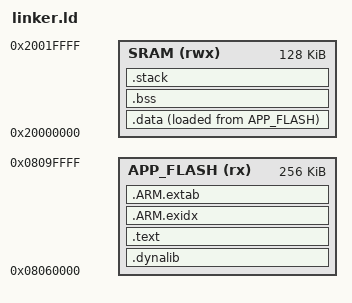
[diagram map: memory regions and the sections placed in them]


/* todo - import defines for mem layout from system module 1 */

MEMORY
{
    APP_FLASH (rx)  : ORIGIN = 0x08060000, LENGTH = 256K

    /* todo - SRAM must start also at an offset after what has been reserved for system-module 1 */
    SRAM      (rwx) : ORIGIN = 0x20000000, LENGTH = 128K
}


SECTIONS
{
    .dynalib :
    {
        link_module_jump_table_start = . ;
        KEEP(*(*.system_part1_module))
        link_module_jump_table_end = . ;
    }>APP_FLASH  AT> APP_FLASH

    .text :
    {
        . = ALIGN(4);

        link_code_location = .;
        KEEP(*(.text.irq ))
        *(.text .text.* .gnu.linkonce.t.*)
        link_code_end = .;

        . = ALIGN(0x4);

        link_const_variable_data_location = .;
        *(.rodata .rodata.* .gnu.linkonce.r.*)
        link_const_variable_data_end = .;

        . = ALIGN(0x4);

        link_constructors_location = .;
        KEEP(*(.preinit_array))
        KEEP(*(.init_array))
        KEEP (*crtbegin.o(.ctors))
        KEEP (*(EXCLUDE_FILE (*crtend.o) .ctors))
        KEEP (*(SORT(.ctors.*)))
        KEEP (*crtend.o(.ctors))
        link_constructors_end = .;

        . = ALIGN(0x4);

        link_destructors_location = .;
        KEEP (*crtbegin.o(.dtors))
        KEEP (*(EXCLUDE_FILE (*crtend.o) .dtors))
        KEEP (*(SORT(.dtors.*)))
        KEEP (*crtend.o(.dtors))
        link_destructors_end = .;

        . = ALIGN(16);

    }>APP_FLASH  AT> APP_FLASH

    /*
     * The .ARM.exidx and .ARM.extab sections are used for C++ exception handling.
     * It is located here for completeness. Bare-metal ARM projects
     * typically cannot afford the overhead associated with C++
     * exceptions handling.
     */
    .ARM.exidx :
    {
        __exidx_start = ALIGN(4);
        *(.ARM.exidx* .gnu.linkonce.armexidx.*)
        __exidx_end = .;
    } > APP_FLASH  AT> APP_FLASH

    .ARM.extab :
    {
        __extab_start = ALIGN(4);
        *(.ARM.extab*)
        __extab_end = .;
    } > APP_FLASH  AT> APP_FLASH

    .data : /* Contains the non-zero initialised global variables */
    {
        link_global_data_initial_values = LOADADDR( .data ); /* This is the location in flash of the initial values of global variables */
        link_global_data_start = .;
        *(.data*)
        link_global_data_end = .;
        . = ALIGN(., 4);
    }> SRAM AT> APP_FLASH


    .bss : /* Zero initialised memory used for zero initialised variables */
    {
        link_bss_location = ALIGN(., 4);
        *(.bss*)
        *(COMMON)
        link_bss_end = .;
        . = ALIGN(., 4);
    }> SRAM AT> SRAM

    .stack : /* Contains the initial stack */
    {
        link_stack_location = ALIGN(., 4);
        *(.stack)
        . = ALIGN(MAX(link_stack_location + __STACKSIZE__ , .), 4);
        link_stack_end = .;
    }> SRAM AT> SRAM

    /DISCARD/ :
    {
        *(.ARM.attributes*)
        *(.comment)
        *(.init)
        *(.preinit)
        *(.fini)
        *(.fini_array)
        *(.ARM.exidx*)
        *(.gnu.linkonce.armexidx.*)
        *(.eh_frame_hdr)
        *(.eh_frame)
        *(.gnu.linkonce.armextab.*)
        *(.v4_bx)
        *(.vfp11_veneer)
        *(.gcc_except_table)
        *(.eh_frame_hdr)
        *(.eh_frame)
        *(.glue*)
    }

}

/* Declare libc Heap to start at end of allocated RAM */

PROVIDE( _heap = link_stack_end );

/* End of the heap is top of RAM, aligned 8 byte */

PROVIDE( _eheap = ALIGN( ORIGIN( SRAM ) + LENGTH( SRAM ) - 8, 8 ) );

ASSERT( link_module_jump_table_start == ORIGIN(APP_FLASH), "module master jump table should be at start of APP FLASH" );
ASSERT( link_module_jump_table_end != link_module_jump_table_start, "module master jump table not linked" );

INCLUDE wifi_export.ld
